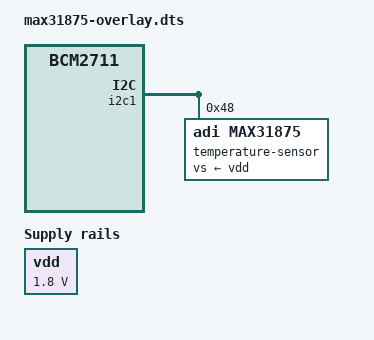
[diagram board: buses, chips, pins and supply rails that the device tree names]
// SPDX-License-Identifier: GPL-2.0
/* Overlay for MAX31875
 *
 * Copyright 2026 Analog Devices Inc.
 */

 /dts-v1/;
 /plugin/;

/ {
	compatible = "bcrm, bcm2711";
};

&{/} {
	vdd: regulator {
		compatible = "regulator-fixed";
		regulator-name = "vref";
		regulator-min-microvolt = <1800000>;
		regulator-max-microvolt = <1800000>;
		regulator-boot-on;
		regulator-always-on;
	};
};

&i2c1 {
	#address-cells = <1>;
	#size-cells = <0>;
	status = "okay";

	temperature-sensor@48 {
		compatible = "adi,max31875";
		reg = <0x48>;
		vs-supply = <&vdd>;
	};
};
